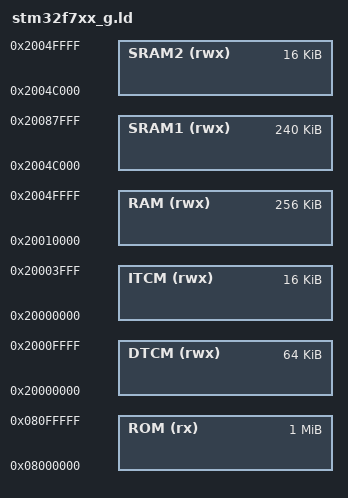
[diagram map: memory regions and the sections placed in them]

MEMORY
{
	ROM (rx)    : ORIGIN = 0x08000000, LENGTH = 1m
	RAM (rwx)   : ORIGIN = 0x20010000, LENGTH = 240k + 16k

	SRAM1 (rwx) : ORIGIN = 0x2004C000, LENGTH = 240k
	SRAM2 (rwx) : ORIGIN = 0x2004C000, LENGTH = 16k
	DTCM (rwx)  : ORIGIN = 0x20000000, LENGTH = 64k
	ITCM (rwx)  : ORIGIN = 0x20000000, LENGTH = 16k
}

INCLUDE stm32_ram.ld
